# ATSAMA5D27WLSOM1 device description
Architecture: CORTEX-A5; Family: SAMA5; Series: SAMA5D2
Registers are 32-bit, read-write, no defined reset value unless marked. A register's access mark holds for its fields unless they carry their own. Offsets are from the block's base; [hi:lo] are bit positions; {n}, {i} and the like mark numbered series; <NAME> marks a mode.

## MPDDRC — AHB Multiport DDR-SDRAM Controller
Instances: MPDDRC 0xF000C000
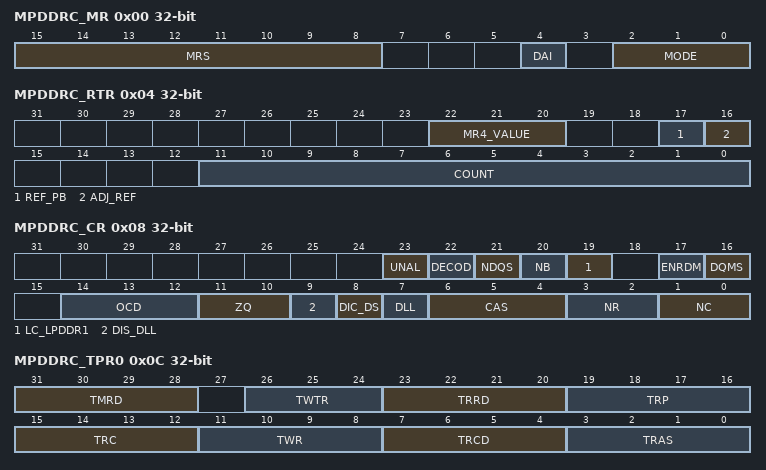
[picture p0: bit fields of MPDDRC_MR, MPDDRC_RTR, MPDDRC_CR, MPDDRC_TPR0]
0x00 MPDDRC_MR — Mode Register
  [15:8] MRS — Mode Register Select LPDDR2/LPDDR3
  [4] DAI — Device Autoinitialization Status (read-only)
    0=DAI_COMPLETE; 1=DAI_IN_PROGESSS (DAI still in progress)
  [2:0] MODE — MPDDRC Command Mode
    0=NORMAL_CMD (Normal Mode. Any access to the MPDDRC is decoded normally. To activate this mode, the command must be followed by a write to the DDR-SDRAM.); 1=NOP_CMD (The MPDDRC issues a NOP command when the DDR-SDRAM device is accessed regardless of the cycle. To activate this mode, the command must be followed by a write to the DDR-SDRAM.); 2=PRCGALL_CMD (The MPDDRC issues the All Banks Precharge command when the DDR-SDRAM device is accessed regardless of the cycle. To activate this mode, the command must be followed by a write to the SDRAM.); 3=LMR_CMD (The MPDDRC issues a Load Mode Register command when the DDR-SDRAM device is accessed regardless of the cycle. To activate this mode, the command must be followed by a write to the DDR-SDRAM.); 4=RFSH_CMD (The MPDDRC issues an Autorefresh command when the DDR-SDRAM device is accessed regardless of the cycle. Previously, an All Banks Precharge command must be issued. To activate this mode, the command must be followed by a write to the DDR-SDRAM.); 5=EXT_LMR_CMD (The MPDDRC issues an Extended Load Mode Register command when the SDRAM device is accessed regardless of the cycle. To activate this mode, the command must be followed by a write to the DDR-SDRAM. The write in the DDR-SDRAM must be done in the appropriate bank.); 6=DEEP_CALIB_MD (Deep Power mode: Access to Deep Powerdown modeCalibration command: to calibrate RTT and RON values for the Process Voltage Temperature (PVT) (DDR3-SDRAM device)); 7=LPDDR2_LPDDR3_CMD (The MPDDRC issues an LPDDR2/LPDDR3 Mode Register command when the device is accessed regardless of the cycle. To activate this mode, the Mode Register command must be followed by a write to the low-power DDR2-SDRAM or to the low-power DDR3-SDRAM.)
0x04 MPDDRC_RTR — Refresh Timer Register
  [22:20] MR4_VALUE — Content of MR4 Register (read-only)
  [17] REF_PB — Refresh Per Bank
  [16] ADJ_REF — Adjust Refresh Rate
  [11:0] COUNT — MPDDRC Refresh Timer Count
0x08 MPDDRC_CR — Configuration Register
  [23] UNAL — Support Unaligned Access
    0=UNSUPPORTED (Unaligned access is not supported.); 1=SUPPORTED (Unaligned access is supported.)
  [22] DECOD — Type of Decoding
    0=SEQUENTIAL (Method for address mapping where banks alternate at each last DDR-SDRAM page of the current bank.); 1=INTERLEAVED (Method for address mapping where banks alternate at each DDR-SDRAM end of page of the current bank.)
  [21] NDQS — Not DQS
    0=ENABLED (Not DQS is enabled); 1=DISABLED (Not DQS is disabled)
  [20] NB — Number of Banks
    0=_4_BANKS (4-bank memory devices); 1=_8_BANKS (8 banks. Only possible when using the DDR2-SDRAM and low-power DDR2-SDRAM and DDR3-SDRAM and low-power DDR3-SDRAM devices.)
  [19] LC_LPDDR1 — Low-cost Low-power DDR1
    0=NOT_2_BANKS (Any type of memory devices except of low cost, low density Low Power DDR1.); 1=_2_BANKS_LPDDR1 (Low-cost and low-density low-power DDR1. These devices have a density of 32 Mbits and are organized as two internal banks. To use this feature, the user has to define the type of memory and the data bus width (see Section 8.8 "MPDDRC Memory Device Register").The 16-bit memory device is organized as 2 banks, 9 columns and 11 rows.The 32-bit memory device is organized as 2 banks, 8 columns and 11 rows.It is impossible to use two 16-bit memory devices (2 x 32 Mbits) for creating one 32-bit memory device (64 Mbits). In this case, it is recommended to use one 32-bit memory device which embeds four internal banks.)
  [17] ENRDM — Enable Read Measure
    0=OFF (DQS/DDR_DATA phase error correction is disabled); 1=ON (DQS/DDR_DATA phase error correction is enabled)
  [16] DQMS — Mask Data is Shared
    0=NOT_SHARED (DQM is not shared with another controller); 1=SHARED (DQM is shared with another controller)
  [14:12] OCD — Off-chip Driver
    0=DDR2_EXITCALIB (Exit from OCD Calibration mode and maintain settings); 7=DDR2_DEFAULT_CALIB (OCD calibration default)
  [11:10] ZQ — ZQ Calibration
    0=INIT (Calibration command after initialization); 1=LONG (Long calibration); 2=SHORT (Short calibration); 3=RESET (ZQ Reset)
  [9] DIS_DLL — DISABLE DLL
  [8] DIC_DS — Output Driver Impedance Control (Drive Strength)
    0=DDR2_NORMALSTRENGTH_DDR3_RZQ6 (Normal drive strength (DDR2) - RZQ/6 (40 [NOM], DDR3)); 1=DDR2_WEAKSTRENGTH_DDR3_RZQ7 (Weak drive strength (DDR2) - RZQ/7 (34 [NOM], DDR3))
  [7] DLL — Reset DLL
    0=RESET_DISABLED (Disable DLL reset); 1=RESET_ENABLED (Enable DLL reset)
  [6:4] CAS — CAS Latency
    2=DDR_CAS2 (LPDDR1 CAS Latency 2); 3=DDR_CAS3 (LPDDR3/DDR2/LPDDR2/LPDDR1 CAS Latency 3); 5=DDR_CAS5 (DDR3 CAS Latency 5); 6=DDR_CAS6 (DDR3LPDDR3 CAS Latency 6)
  [3:2] NR — Number of Row Bits
    0=_11_ROW_BITS (11 bits to define the row number, up to 2048 rows); 1=_12_ROW_BITS (12 bits to define the row number, up to 4096 rows); 2=_13_ROW_BITS (13 bits to define the row number, up to 8192 rows); 3=_14_ROW_BITS (14 bits to define the row number, up to 16384 rows)
  [1:0] NC — Number of Column Bits
    0=DDR9_MDDR8_COL_BITS (9 bits to define the column number, up to 512 columns, for DDR2-SDRAM/DDR3-SDRAM/LPDDR2-SDRAM/LPDDR3-SDRAM 8 bits to define the column number, up to 256 columns, for LPDDR1-SDRAM); 1=DDR10_MDDR9_COL_BITS (10 bits to define the column number, up to 1024 columns, for DDR2-SDRAM/DDR3-SDRAM/LPDDR2-SDRAM/LPDDR3-SDRAM 9 bits to define the column number, up to 512 columns, for LPDDR1-SDRAM); 2=DDR11_MDDR10_COL_BITS (11 bits to define the column number, up to 2048 columns, for DDR2-SDRAM/DDR3-SDRAM/LPDDR2-SDRAM/LPDDR3-SDRAM 10 bits to define the column number, up to 1024 columns, for LPDDR1-SDRAM); 3=DDR12_MDDR11_COL_BITS (12 bits to define the column number, up to 4096 columns, for DDR2-SDRAM/DDR3-SDRAM/LPDDR2-SDRAM/LPDDR3-SDRAM 11 bits to define the column number, up to 2048 columns, for LPDDR1-SDRAM)
0x0C MPDDRC_TPR0 — Timing Parameter 0 Register
  [31:28] TMRD — Load Mode Register Command to Activate or Refresh Command
  [26:24] TWTR — Internal Write to Read Delay
  [23:20] TRRD — Active BankA to Active BankB
  [19:16] TRP — Row Precharge Delay
  [15:12] TRC — Row Cycle Delay
  [11:8] TWR — Write Recovery Delay
  [7:4] TRCD — Row to Column Delay
  [3:0] TRAS — Active to Precharge Delay
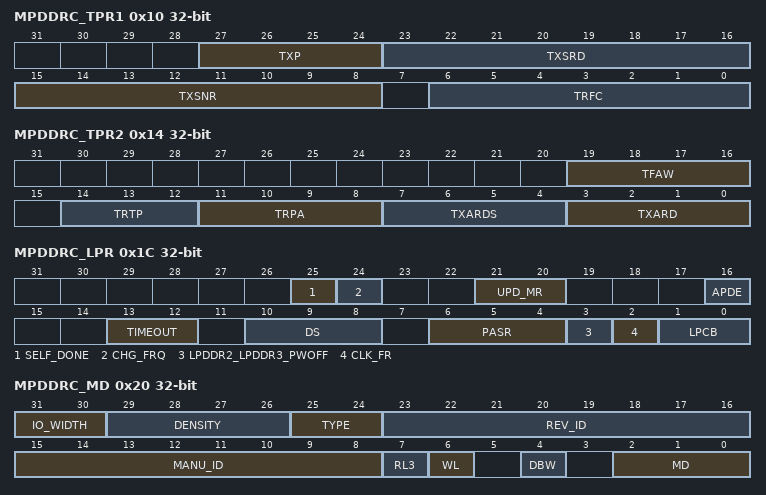
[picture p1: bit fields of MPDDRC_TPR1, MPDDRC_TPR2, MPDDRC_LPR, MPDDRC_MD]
0x10 MPDDRC_TPR1 — Timing Parameter 1 Register
  [27:24] TXP — Exit Powerdown Delay to First Command
  [23:16] TXSRD — Exit Self-refresh Delay to Read Command
  [15:8] TXSNR — Exit Self-refresh Delay to Non-Read Command
  [6:0] TRFC — Row Cycle Delay
0x14 MPDDRC_TPR2 — Timing Parameter 2 Register
  [19:16] TFAW — Four Active Windows
  [14:12] TRTP — Read to Precharge
  [11:8] TRPA — Row Precharge All Delay
  [7:4] TXARDS — Exit Active Power Down Delay to Read Command in Mode "Slow Exit"
  [3:0] TXARD — Exit Active Power Down Delay to Read Command in Mode "Fast Exit"
0x1C MPDDRC_LPR — Low-Power Register
  [25] SELF_DONE — Self-refresh is done (read-only)
  [24] CHG_FRQ — Change Clock Frequency During Self-refresh Mode
  [21:20] UPD_MR — Update Load Mode Register and Extended Mode Register
    0=NO_UPDATE (Update of Load Mode and Extended Mode registers is disabled.); 1=UPDATE_SHAREDBUS (MPDDRC shares an external bus. Automatic update is done during a refresh command and a pending read or write access in the SDRAM device.); 2=UPDATE_NOSHAREDBUS (MPDDRC does not share an external bus. Automatic update is done before entering Self-refresh mode.)
  [16] APDE — Active Power Down Exit Time
    0=DDR2_FAST_EXIT (Fast Exit from Power Down. DDR2-SDRAM and DDR3-SDRAM devices only.); 1=DDR2_SLOW_EXIT (Slow Exit from Power Down. DDR2-SDRAM and DDR3-SDRAM devices only.)
  [13:12] TIMEOUT — Time Between Last Transfer and Low-Power Mode
    0=NONE (SDRAM Low-power mode is activated immediately after the end of the last transfer.); 1=DELAY_64_CLK (SDRAM Low-power mode is activated 64 clock cycles after the end of the last transfer.); 2=DELAY_128_CLK (SDRAM Low-power mode is activated 128 clock cycles after the end of the last transfer.)
  [10:8] DS — Drive Strength
    0=DS_FULL (Full drive strength); 1=DS_HALF (Half drive strength); 2=DS_QUARTER (Quarter drive strength); 3=DS_OCTANT (Octant drive strength)
  [6:4] PASR — Partial Array Self-refresh
  [3] LPDDR2_LPDDR3_PWOFF — LPDDR2 - LPDDR3 Power Off Bit
    0=DISABLED (No power-off sequence applied to LPDDR2/LPDDR3.); 1=ENABLED (A power-off sequence is applied to the LPDDR2/LPDDR3 device. CKE is forced low.)
  [2] CLK_FR — Clock Frozen Command Bit
    0=DISABLED (Clock(s) is/are not frozen.); 1=ENABLED (Clock(s) is/are frozen.)
  [1:0] LPCB — Low-power Command Bit
    0=NOLOWPOWER (Low-power feature is inhibited. No Powerdown, Self-refresh and Deep power modes are issued to the DDR-SDRAM device.); 1=SELFREFRESH (The MPDDRC issues a self-refresh command to the DDR-SDRAM device, the clock(s) is/are deactivated and the CKE signal is set low. The DDR-SDRAM device leaves the Self-refresh mode when accessed and reenters it after the access.); 2=POWERDOWN (The MPDDRC issues a Powerdown command to the DDR-SDRAM device after each access, the CKE signal is set low. The DDR-SDRAM device leaves the Powerdown mode when accessed and reenters it after the access.); 3=DEEPPOWERDOWN (The MPDDRC issues a Deep Powerdown command to the low-power DDR-SDRAM device.)
0x20 MPDDRC_MD — Memory Device Register
  [31:30] IO_WIDTH — Width of Memory (read-only)
    0=WIDTH_32 (The data bus width is 32 bits.); 1=WIDTH_16 (The data bus width is 16 bits.); 2=WIDTH_8 (The data bus width is 8 bits.); 3=NOT_USED
  [29:26] DENSITY — Density of Memory (read-only)
    0=DENSITY_64MBITS (The device density is 64 Mbits.); 1=DENSITY_128MBITS (The device density is 128 Mbits.); 2=DENSITY_256MBITS (The device density is 256 Mbits.); 3=DENSITY_512MBITS (The device density is 512 Mbits.); 4=DENSITY_1GBITS (The device density is 1 Gbit.); 5=DENSITY_2GBITS (The device density is 2 Gbits.); 6=DENSITY_4GBITS (The device density is 4 Gbits.); 7=DENSITY_8GBITS (The device density is 8 Gbits.); 8=DENSITY_16GBITS (The device density is 16 Gbits.); 9=DENSITY_32GBITS (The device density is 32 Gbits.)
  [25:24] TYPE — DRAM Architecture (read-only)
    0=S4_SDRAM (4n prefetch architecture); 1=S2_SDRAM (2n prefetch architecture); 2=NVM (Non-volatile device); 3=S8_SDRAM (8n prefetch architecture)
  [23:16] REV_ID — Revision Identification (read-only)
  [15:8] MANU_ID — Manufacturer Identification (read-only)
  [7] RL3 — Read Latency 3 Option Support (read-only)
    0=RL3_SUPPORT (Read latency of 3 is supported); 1=RL3_NOT_SUPPORTED (Read latency 0f 3 is not supported)
  [6] WL — Write Latency (read-only)
    0=WL_SETA (Write Latency Set A); 1=WL_SETB (Write Latency Set B)
  [4] DBW — Data Bus Width
    0=DBW_32_BITS (Data bus width is 32 bits); 1=DBW_16_BITS (Data bus width is 16 bits.)
  [2:0] MD — Memory Device
    3=LPDDR_SDRAM (Low-power DDR1-SDRAM); 4=DDR3_SDRAM; 5=LPDDR3_SDRAM (Low-power DDR3-SDRAM); 6=DDR2_SDRAM; 7=LPDDR2_SDRAM (Low-power DDR2-SDRAM)
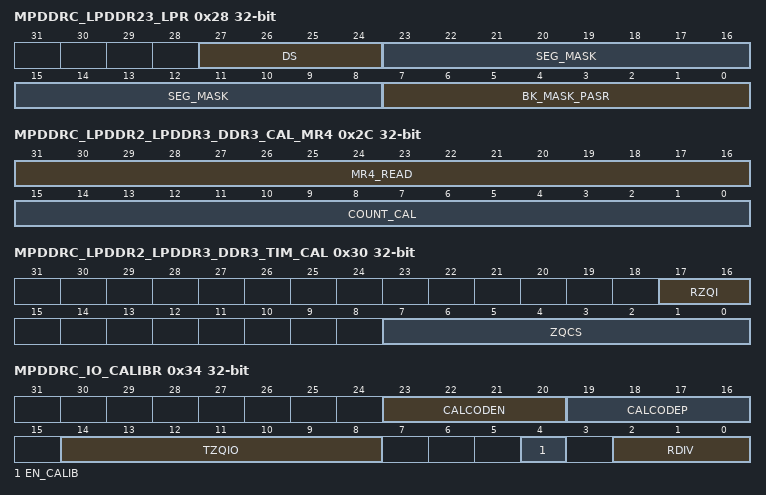
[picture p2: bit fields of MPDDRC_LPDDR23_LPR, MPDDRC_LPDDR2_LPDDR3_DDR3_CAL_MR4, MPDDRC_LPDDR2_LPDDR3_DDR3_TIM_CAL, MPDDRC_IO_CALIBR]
0x28 MPDDRC_LPDDR23_LPR — Low-power DDR2 Low-power DDR3 Low-power Register
  [27:24] DS — Drive Strength
    1=DS_34_3 (34.3 ohm typical); 2=40 ohm typical (default); 3=48 ohm typical; 4=60 ohm typical; 6=80 ohm typical; 7=120 ohm typical
  [23:8] SEG_MASK — Segment Mask Bit
  [7:0] BK_MASK_PASR — Bank Mask Bit/PASR
0x2C MPDDRC_LPDDR2_LPDDR3_DDR3_CAL_MR4 — Low-power DDR2 Low-power DDR3 and DDR3 Calibration and MR4 Register
  [31:16] MR4_READ — Mode Register 4 Read Interval
  [15:0] COUNT_CAL — LPDDR2 LPDDR3 and DDR3 Calibration Timer Count
0x30 MPDDRC_LPDDR2_LPDDR3_DDR3_TIM_CAL — Low-power DDR2 Low-power DDR3 and DDR3 Timing Calibration Register
  [17:16] RZQI — Built-in Self-Test for RZQ Information (read-only)
    0=RZQ_NOT_SUPPORTED (RZQ self test not supported); 1=ZQ_VDDCA_FLOAT (The ZQ pin can be connected to VDDCA or left floating.); 2=ZQ_SHORTED_GROUND (The ZQ pin can be shorted to ground.); 3=ZQ_SELF_TEST_OK (ZQ pin self test complete; no error condition detected)
  [7:0] ZQCS — ZQ Calibration Short
0x34 MPDDRC_IO_CALIBR — I/O Calibration Register
  [23:20] CALCODEN — Number of Transistor N (read-only)
  [19:16] CALCODEP — Number of Transistor P (read-only)
  [14:8] TZQIO — IO Calibration
  [4] EN_CALIB — Enable Calibration
    0=DISABLE_CALIBRATION (Calibration is disabled.); 1=ENABLE_CALIBRATION (Calibration is enabled.)
  [2:0] RDIV — Resistor Divider, Output Driver Impedance
    1=RZQ_34 (LPDDR2 serial impedance line = 34.3 ohms,DDR2/LPDDR1 serial impedance line: Not applicable); 2=RZQ_40_RZQ_38_RZQ_37_RZQ_35 (LPDDR2 serial impedance line = 40 ohms,LPDDR3 serial impedance line = 38 ohms,DDR3 serial impedance line = 37 ohms,DDR2/LPDDR1 serial impedance line = 35 ohms); 3=RZQ_48_RZQ_46_RZQ_44_RZQ_43 (LPDDR2 serial impedance line = 48 ohms,LPDDR3 serial impedance line = 46 ohms,DDR3 serial impedance line = 44 ohms,DDR2/LPDDR1 serial impedance line = 43 ohms); 4=RZQ_60_RZQ_57_RZQ_55_RZQ_52 (LPDDR2 serial impedance line = 60 ohms,LPDDR3 serial impedance line = 57 ohms,DDR3 serial impedance line = 55 ohms,DDR2/LPDDR1 serial impedance line = 52 ohms); 6=RZQ_80_RZQ_77_RZQ_73_RZQ_70 (LPDDR2 serial impedance line = 80 ohms,LPDDR3 serial impedance line = 77 ohms,DDR3 serial impedance line = 73 ohms,DDR2/LPDDR1 serial impedance line = 70 ohms); 7=RZQ_120_RZQ_115_RZQ_110_RZQ_105 (LPDDR2 serial impedance line = 120 ohms,LPDDR3 serial impedance line = 115 ohms,DDR3 serial impedance line = 110 ohms,DDR2/LPDDR1 serial impedance line = 105 ohms)
0x38 MPDDRC_OCMS — OCMS Register
  [0] SCR_EN — Scrambling Enable
0x3C MPDDRC_OCMS_KEY1 wo — OCMS KEY1 Register
  [31:0] KEY1 — Off-chip Memory Scrambling (OCMS) Key Part 1
0x40 MPDDRC_OCMS_KEY2 wo — OCMS KEY2 Register
  [31:0] KEY2 — Off-chip Memory Scrambling (OCMS) Key Part 2
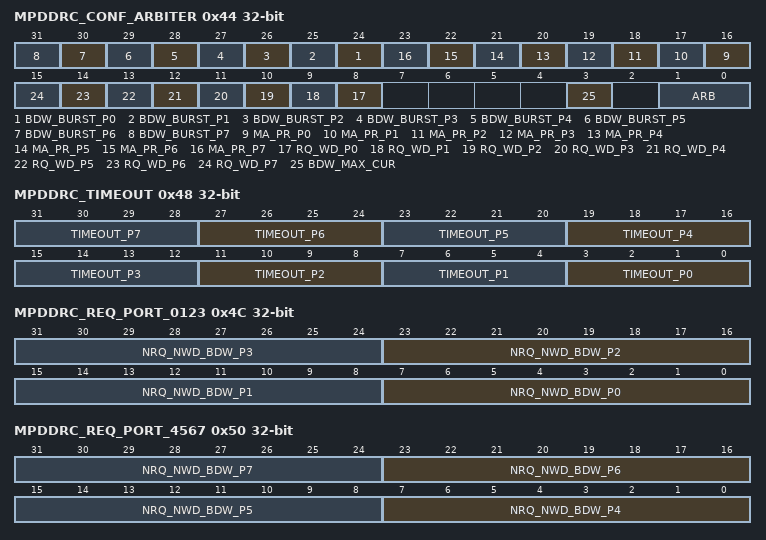
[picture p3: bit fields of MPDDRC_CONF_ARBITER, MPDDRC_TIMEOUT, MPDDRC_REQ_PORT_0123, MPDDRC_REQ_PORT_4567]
0x44 MPDDRC_CONF_ARBITER — Configuration Arbiter Register
  [n+24] BDW_BURST_P{n} (n=0..7) — Bandwidth is Reached or Bandwidth and Current Burst Access is Ended on port X
  [n+16] MA_PR_P{n} (n=0..7) — Master or Software Provide Information
  [n+8] RQ_WD_P{n} (n=0..7) — Request or Word from Port X
  [3] BDW_MAX_CUR — Bandwidth Max or Current
  [1:0] ARB — Type of Arbitration
    0=ROUND (Round Robin); 1=NB_REQUEST (Request Policy); 2=BANDWIDTH (Bandwidth Policy)
0x48 MPDDRC_TIMEOUT — Timeout Register
  [4n+3:4n] TIMEOUT_P{n} (n=0..7) — Timeout for Ports 0, 1, 2, 3, 4, 5, 6 and 7
0x4C MPDDRC_REQ_PORT_0123 — Request Port 0-1-2-3 Register
  [8n+7:8n] NRQ_NWD_BDW_P{n} (n=0..3) — Number of Requests, Number of Words or Bandwidth Allocation from Port 0-1-2-3
0x50 MPDDRC_REQ_PORT_4567 — Request Port 4-5-6-7 Register
  [8n-25:8n-32] NRQ_NWD_BDW_P{n} (n=4..7) — Number of Requests, Number of Words or Bandwidth allocation from port 4-5-6-7
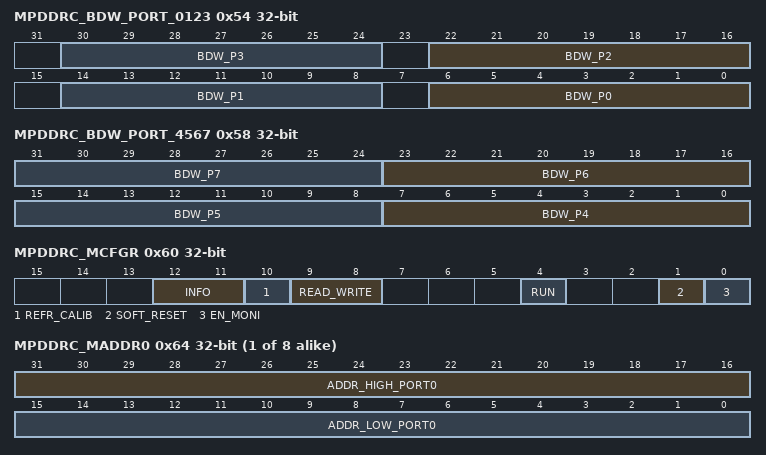
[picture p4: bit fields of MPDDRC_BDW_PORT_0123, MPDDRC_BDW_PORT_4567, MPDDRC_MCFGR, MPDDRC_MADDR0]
0x54 MPDDRC_BDW_PORT_0123 ro — Current/Maximum Bandwidth Port 0-1-2-3 Register
  [8n+6:8n] BDW_P{n} (n=0..3) — Current/Maximum Bandwidth from Port 0-1-2-3
0x58 MPDDRC_BDW_PORT_4567 ro — Current/Maximum Bandwidth Port 4-5-6-7 Register
  [8n-25:8n-32] BDW_P{n} (n=4..7) — Current/Maximum Bandwidth from Port 4-5-6-7
0x5C MPDDRC_RD_DATA_PATH — Read Data Path Register
  [1:0] SHIFT_SAMPLING — Shift Sampling Point of Data
    0=NO_SHIFT (Initial sampling point.); 1=SHIFT_ONE_CYCLE (Sampling point is shifted by one cycle.); 2=SHIFT_TWO_CYCLES (Sampling point is shifted by two cycles.); 3=SHIFT_THREE_CYCLES (Sampling point is shifted by three cycles, unique for LPDDR2 and DDR3 and LPDDR3.Not applicable for DDR2 and LPDDR1 devices.)
0x60 MPDDRC_MCFGR — Monitor Configuration Register
  [12:11] INFO — Information Type
    0=MAX_WAIT (Information concerning the transfer with the longest waiting time); 1=NB_TRANSFERS (Number of transfers on the port); 2=TOTAL_LATENCY (Total latency on the port)
  [10] REFR_CALIB — Refresh Calibration
  [9:8] READ_WRITE — Read/Write Access
    0=TRIG_RD_WR (Read and Write accesses are triggered.); 1=TRIG_WR (Only Write accesses are triggered.); 2=TRIG_RD (Only Read accesses are triggered.)
  [4] RUN — Control Monitor
  [1] SOFT_RESET
  [0] EN_MONI — Enable Monitor
{0x64+4i} MPDDRC_MADDR{i} (i=0..7) — Monitor Address High/Low Port {i} Register
  [31:16] ADDR_HIGH_PORT{i} — Address High on Port x [x = 0..7]
  [15:0] ADDR_LOW_PORT{i} — Address Low on Port x [x = 0..7]
{0x84+4i} MPDDRC_MINFO{i} ro (modes: MAX_WAIT when MPDDRC_MCFGR.INFO=0; NB_TRANSFERS when MPDDRC_MCFGR.INFO=1; TOTAL_LATENCY when MPDDRC_MCFGR.INFO=2) (i=0..7) — Monitor Information Port {i} Register
  [24] READ_WRITE <MAX_WAIT> — Read or Write Access on Port x [x = 0..7]
  [22:20] SIZE <MAX_WAIT> — Transfer Size on Port x [x = 0..7]
    0=_8BITS (Byte transfer); 1=_16BITS (Halfword transfer); 2=_32BITS (Word transfer); 3=_64BITS (Dword transfer)
  [18:16] BURST <MAX_WAIT> — Type of Burst on Port x [x = 0..7]
    0=SINGLE (Single transfer); 1=INCR (Incrementing burst of unspecified length); 2=WRAP4 (4-beat wrapping burst); 3=INCR4 (4-beat incrementing burst); 4=WRAP8 (8-beat wrapping burst); 5=INCR8 (8-beat incrementing burst); 6=WRAP16 (16-beat wrapping burst); 7=INCR16 (16-beat incrementing burst)
  [15:0] MAX_PORT{i}_WAITING <MAX_WAIT> — Address High on Port x [x = 0..7]
  [31:0] P{i}_NB_TRANSFERS <NB_TRANSFERS> — Number of Transfers on Port x [x = 0..7]
  [31:0] P{i}_TOTAL_LATENCY <TOTAL_LATENCY> — Total Latency on Port x [x = 0..7]
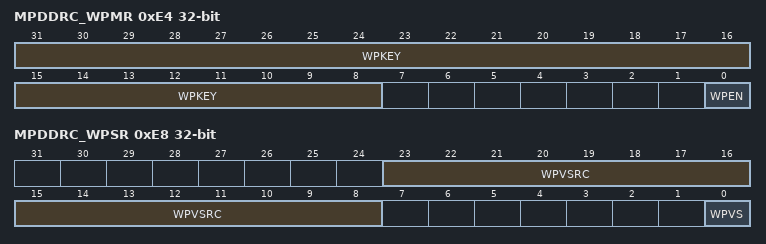
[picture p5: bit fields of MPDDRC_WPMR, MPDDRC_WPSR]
0xE4 MPDDRC_WPMR — Write Protection Mode Register
  [31:8] WPKEY — Write Protection Key
    0x444452=PASSWD (Writing any other value in this field aborts the write operation of the WPEN bit.Always reads as 0.)
  [0] WPEN — Write Protection Enable
0xE8 MPDDRC_WPSR ro — Write Protection Status Register
  [23:8] WPVSRC — Write Protection Violation Source
  [0] WPVS — Write Protection Enable
